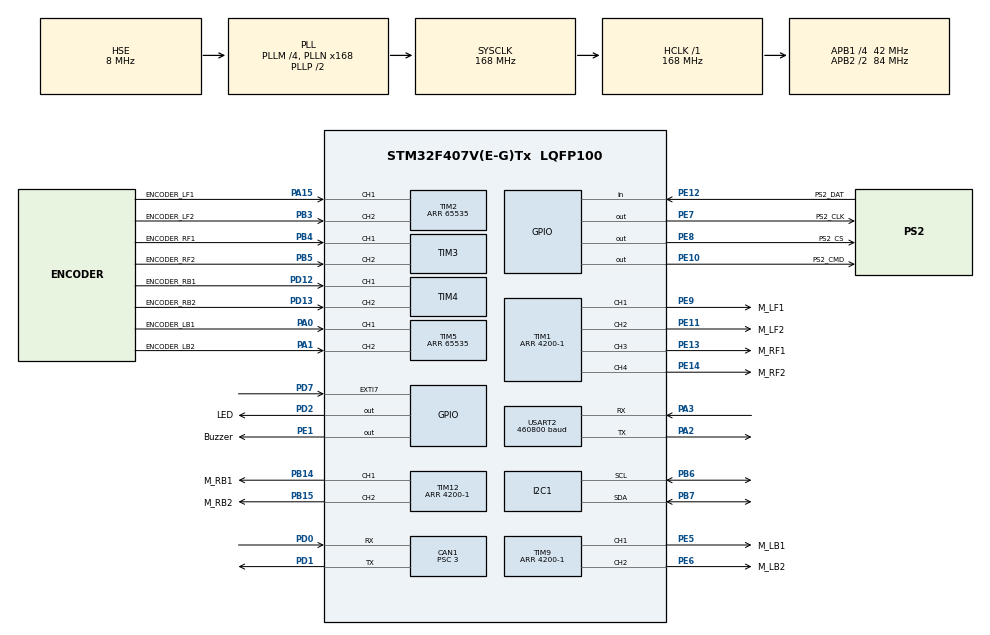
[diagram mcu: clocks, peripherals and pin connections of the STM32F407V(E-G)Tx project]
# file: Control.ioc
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CAN1.ABOM=ENABLE
CAN1.AWUM=ENABLE
CAN1.BS1=CAN_BS1_10TQ
CAN1.BS2=CAN_BS2_3TQ
CAN1.CalculateBaudRate=1000000
CAN1.CalculateTimeBit=1000
CAN1.CalculateTimeQuantum=71.42857142857143
CAN1.NART=ENABLE
CAN1.Prescaler=3
CAN1.TXFP=ENABLE
Dma.Request0=USART2_RX
Dma.Request1=USART2_TX
Dma.USART2_RX.0.Direction=DMA_PERIPH_TO_MEMORY
Dma.USART2_RX.0.FIFOMode=DMA_FIFOMODE_DISABLE
Dma.USART2_RX.0.Instance=DMA1_Stream5
Dma.USART2_RX.0.MemDataAlignment=DMA_MDATAALIGN_BYTE
Dma.USART2_RX.0.MemInc=DMA_MINC_ENABLE
Dma.USART2_RX.0.Mode=DMA_CIRCULAR
Dma.USART2_RX.0.PeriphDataAlignment=DMA_PDATAALIGN_BYTE
Dma.USART2_RX.0.PeriphInc=DMA_PINC_DISABLE
Dma.USART2_RX.0.Priority=DMA_PRIORITY_LOW
Dma.USART2_TX.1.Direction=DMA_MEMORY_TO_PERIPH
Dma.USART2_TX.1.FIFOMode=DMA_FIFOMODE_DISABLE
Dma.USART2_TX.1.Instance=DMA1_Stream6
Dma.USART2_TX.1.MemDataAlignment=DMA_MDATAALIGN_BYTE
Dma.USART2_TX.1.MemInc=DMA_MINC_ENABLE
Dma.USART2_TX.1.Mode=DMA_CIRCULAR
Dma.USART2_TX.1.PeriphDataAlignment=DMA_PDATAALIGN_BYTE
Dma.USART2_TX.1.PeriphInc=DMA_PINC_DISABLE
Dma.USART2_TX.1.Priority=DMA_PRIORITY_LOW
FREERTOS.Tasks01=MonitorTask,1,128,StartMonitorTask,As weak,NULL,Dynamic,NULL,NULL;System,-1,256,StartSystemTask,As external,NULL,Dynamic,NULL,NULL;Control,0,512,StartControlTask,As external,NULL,Dynamic,NULL,NULL
I2C1.I2C_Mode=I2C_Fast
Mcu.Family=STM32F4
Mcu.Name=STM32F407V(E-G)Tx
Mcu.Package=LQFP100
NVIC.CAN1_RX0_IRQn=true\:5\:0\:false\:false\:true\:true\:true\:true\:true
NVIC.DMA1_Stream5_IRQn=true\:5\:0\:false\:false\:true\:true\:false\:true\:true
NVIC.DMA1_Stream6_IRQn=true\:5\:0\:false\:false\:true\:true\:false\:true\:true
NVIC.EXTI9_5_IRQn=true\:5\:0\:false\:false\:true\:true\:true\:true\:true
NVIC.PriorityGroup=NVIC_PRIORITYGROUP_4
NVIC.TIM8_UP_TIM13_IRQn=true\:15\:0\:false\:false\:true\:false\:false\:true\:true
NVIC.TimeBase=TIM8_UP_TIM13_IRQn
NVIC.TimeBaseIP=TIM8
NVIC.USART2_IRQn=true\:5\:0\:false\:false\:true\:true\:false\:true\:true
PA0-WKUP.GPIO_Label=ENCODER_LB1
PA0-WKUP.GPIO_Speed=GPIO_SPEED_FREQ_VERY_HIGH
PA0-WKUP.Signal=S_TIM5_CH1
PA1.GPIO_Label=ENCODER_LB2
PA1.GPIO_Speed=GPIO_SPEED_FREQ_VERY_HIGH
PA1.Signal=S_TIM5_CH2
PA13.Mode=Serial_Wire
PA13.Signal=SYS_JTMS-SWDIO
PA14.Mode=Serial_Wire
PA14.Signal=SYS_JTCK-SWCLK
PA15.GPIO_Label=ENCODER_LF1
PA15.GPIO_PuPd=GPIO_PULLUP
PA15.GPIO_Speed=GPIO_SPEED_FREQ_VERY_HIGH
PA15.Signal=S_TIM2_CH1_ETR
PA2.Mode=Asynchronous
PA2.Signal=USART2_TX
PA3.Mode=Asynchronous
PA3.Signal=USART2_RX
PB14.GPIO_Label=M_RB1
PB14.GPIO_PuPd=GPIO_PULLUP
PB14.GPIO_Speed=GPIO_SPEED_FREQ_HIGH
PB14.Signal=S_TIM12_CH1
PB15.GPIO_Label=M_RB2
PB15.GPIO_PuPd=GPIO_PULLUP
PB15.GPIO_Speed=GPIO_SPEED_FREQ_HIGH
PB15.Signal=S_TIM12_CH2
PB3.GPIO_Label=ENCODER_LF2
PB3.GPIO_PuPd=GPIO_PULLUP
PB3.GPIO_Speed=GPIO_SPEED_FREQ_VERY_HIGH
PB3.Signal=S_TIM2_CH2
PB4.GPIO_Label=ENCODER_RF1
PB4.GPIO_Speed=GPIO_SPEED_FREQ_VERY_HIGH
PB4.Signal=S_TIM3_CH1
PB5.GPIO_Label=ENCODER_RF2
PB5.GPIO_Speed=GPIO_SPEED_FREQ_VERY_HIGH
PB5.Signal=S_TIM3_CH2
PB6.GPIO_Pu=GPIO_PULLUP
PB6.Mode=I2C
PB6.Signal=I2C1_SCL
PB7.GPIO_Pu=GPIO_PULLUP
PB7.Mode=I2C
PB7.Signal=I2C1_SDA
PD0.Mode=CAN_Activate
PD0.Signal=CAN1_RX
PD1.Mode=CAN_Activate
PD1.Signal=CAN1_TX
PD12.GPIO_Label=ENCODER_RB1
PD12.GPIO_Speed=GPIO_SPEED_FREQ_VERY_HIGH
PD12.Signal=S_TIM4_CH1
PD13.GPIO_Label=ENCODER_RB2
PD13.GPIO_Speed=GPIO_SPEED_FREQ_VERY_HIGH
PD13.Signal=S_TIM4_CH2
PD2.GPIO_Label=LED
PD2.GPIO_Speed=GPIO_SPEED_FREQ_HIGH
PD2.Signal=GPIO_Output
PD7.GPIO_ModeDefaultEXTI=GPIO_MODE_IT_RISING_FALLING
PD7.GPIO_PuPd=GPIO_PULLUP
PD7.Signal=GPXTI7
PE1.GPIO_Label=Buzzer
PE1.GPIO_Speed=GPIO_SPEED_FREQ_HIGH
PE1.Signal=GPIO_Output
PE10.GPIO_Label=PS2_CMD
PE10.GPIO_PuPd=GPIO_PULLUP
PE10.GPIO_Speed=GPIO_SPEED_FREQ_HIGH
PE10.PinState=GPIO_PIN_SET
PE10.Signal=GPIO_Output
PE11.GPIO_Label=M_LF2
PE11.GPIO_PuPd=GPIO_PULLUP
PE11.GPIO_Speed=GPIO_SPEED_FREQ_HIGH
PE11.Signal=S_TIM1_CH2
PE12.GPIO_Label=PS2_DAT
PE12.GPIO_PuPd=GPIO_PULLUP
PE12.Signal=GPIO_Input
PE13.GPIO_Label=M_RF1
PE13.GPIO_PuPd=GPIO_PULLUP
PE13.GPIO_Speed=GPIO_SPEED_FREQ_HIGH
PE13.Signal=S_TIM1_CH3
PE14.GPIO_Label=M_RF2
PE14.GPIO_PuPd=GPIO_PULLUP
PE14.GPIO_Speed=GPIO_SPEED_FREQ_HIGH
PE14.Signal=S_TIM1_CH4
PE5.GPIO_Label=M_LB1
PE5.GPIO_PuPd=GPIO_PULLUP
PE5.GPIO_Speed=GPIO_SPEED_FREQ_HIGH
PE5.Signal=S_TIM9_CH1
PE6.GPIO_Label=M_LB2
PE6.GPIO_PuPd=GPIO_PULLUP
PE6.GPIO_Speed=GPIO_SPEED_FREQ_HIGH
PE6.Signal=S_TIM9_CH2
PE7.GPIO_Label=PS2_CLK
PE7.GPIO_PuPd=GPIO_PULLUP
PE7.GPIO_Speed=GPIO_SPEED_FREQ_HIGH
PE7.PinState=GPIO_PIN_SET
PE7.Signal=GPIO_Output
PE8.GPIO_Label=PS2_CS
PE8.GPIO_PuPd=GPIO_PULLUP
PE8.GPIO_Speed=GPIO_SPEED_FREQ_HIGH
PE8.PinState=GPIO_PIN_SET
PE8.Signal=GPIO_Output
PE9.GPIO_Label=M_LF1
PE9.GPIO_PuPd=GPIO_PULLUP
PE9.GPIO_Speed=GPIO_SPEED_FREQ_HIGH
PE9.Signal=S_TIM1_CH1
PH0-OSC_IN.Mode=HSE-External-Oscillator
PH0-OSC_IN.Signal=RCC_OSC_IN
PH1-OSC_OUT.Mode=HSE-External-Oscillator
PH1-OSC_OUT.Signal=RCC_OSC_OUT
ProjectManager.HeapSize=0x200
ProjectManager.StackSize=0x400
ProjectManager.TargetToolchain=MDK-ARM V5.32
RCC.48MHZClocksFreq_Value=84000000
RCC.AHBFreq_Value=168000000
RCC.APB1CLKDivider=RCC_HCLK_DIV4
RCC.APB1Freq_Value=42000000
RCC.APB1TimFreq_Value=84000000
RCC.APB2CLKDivider=RCC_HCLK_DIV2
RCC.APB2Freq_Value=84000000
RCC.APB2TimFreq_Value=168000000
RCC.CortexFreq_Value=168000000
RCC.HCLKFreq_Value=168000000
RCC.HSE_VALUE=8000000
RCC.HSI_VALUE=16000000
RCC.LSE_VALUE=32768
RCC.PLLM=4
RCC.PLLN=168
RCC.PLLSourceVirtual=RCC_PLLSOURCE_HSE
RCC.SYSCLKFreq_VALUE=168000000
RCC.SYSCLKSource=RCC_SYSCLKSOURCE_PLLCLK
RCC.VCOOutputFreq_Value=336000000
SH.S_TIM12_CH1.0=TIM12_CH1,PWM Generation1 CH1
SH.S_TIM12_CH2.0=TIM12_CH2,PWM Generation2 CH2
SH.S_TIM1_CH1.0=TIM1_CH1,PWM Generation1 CH1
SH.S_TIM1_CH2.0=TIM1_CH2,PWM Generation2 CH2
SH.S_TIM1_CH3.0=TIM1_CH3,PWM Generation3 CH3
SH.S_TIM1_CH4.0=TIM1_CH4,PWM Generation4 CH4
SH.S_TIM2_CH1_ETR.0=TIM2_CH1,Encoder_Interface
SH.S_TIM2_CH2.0=TIM2_CH2,Encoder_Interface
SH.S_TIM3_CH1.0=TIM3_CH1,Encoder_Interface
SH.S_TIM3_CH2.0=TIM3_CH2,Encoder_Interface
SH.S_TIM4_CH1.0=TIM4_CH1,Encoder_Interface
SH.S_TIM4_CH2.0=TIM4_CH2,Encoder_Interface
SH.S_TIM5_CH1.0=TIM5_CH1,Encoder_Interface
SH.S_TIM5_CH2.0=TIM5_CH2,Encoder_Interface
SH.S_TIM9_CH1.0=TIM9_CH1,PWM Generation1 CH1
SH.S_TIM9_CH2.0=TIM9_CH2,PWM Generation2 CH2
TIM1.AutoReloadPreload=TIM_AUTORELOAD_PRELOAD_ENABLE
TIM1.AutomaticOutput=TIM_AUTOMATICOUTPUT_ENABLE
TIM1.BreakState=TIM_BREAK_ENABLE
TIM1.Channel-PWM\ Generation1\ CH1=TIM_CHANNEL_1
TIM1.Channel-PWM\ Generation2\ CH2=TIM_CHANNEL_2
TIM1.Channel-PWM\ Generation3\ CH3=TIM_CHANNEL_3
TIM1.Channel-PWM\ Generation4\ CH4=TIM_CHANNEL_4
TIM1.LockLevel=TIM_LOCKLEVEL_1
TIM1.Period=4200-1
TIM10.AutoReloadPreload=TIM_AUTORELOAD_PRELOAD_ENABLE
TIM10.Period=20000-1
TIM10.Prescaler=168-1
TIM11.AutoReloadPreload=TIM_AUTORELOAD_PRELOAD_ENABLE
TIM11.Period=20000-1
TIM11.Prescaler=168-1
TIM12.AutoReloadPreload=TIM_AUTORELOAD_PRELOAD_ENABLE
TIM12.Channel-PWM\ Generation1\ CH1=TIM_CHANNEL_1
TIM12.Channel-PWM\ Generation2\ CH2=TIM_CHANNEL_2
TIM12.Period=4200-1
TIM2.EncoderMode=TIM_ENCODERMODE_TI12
TIM2.Period=65535
TIM3.EncoderMode=TIM_ENCODERMODE_TI12
TIM4.EncoderMode=TIM_ENCODERMODE_TI12
TIM5.EncoderMode=TIM_ENCODERMODE_TI12
TIM5.Period=65535
TIM9.AutoReloadPreload=TIM_AUTORELOAD_PRELOAD_ENABLE
TIM9.Channel-PWM\ Generation1\ CH1=TIM_CHANNEL_1
TIM9.Channel-PWM\ Generation2\ CH2=TIM_CHANNEL_2
TIM9.Period=4200-1
USART2.BaudRate=460800
USART2.VirtualMode=VM_ASYNC
VP_FREERTOS_VS_CMSIS_V1.Mode=CMSIS_V1
VP_IWDG_VS_IWDG.Mode=IWDG_Activate
VP_SYS_VS_tim8.Mode=TIM8
VP_TIM10_VS_ClockSourceINT.Mode=Enable_Timer
VP_TIM11_VS_ClockSourceINT.Mode=Enable_Timer
board=custom

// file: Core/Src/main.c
/* USER CODE BEGIN Header */
/**
  ******************************************************************************
  * @file           : main.c
  * @brief          : Main program body
  ******************************************************************************
  * @attention
  *
  * Copyright (c) 2025 STMicroelectronics.
  * All rights reserved.
  *
  * This software is licensed under terms that can be found in the LICENSE file
  * in the root directory of this software component.
  * If no LICENSE file comes with this software, it is provided AS-IS.
  *
  ******************************************************************************
  */
/* USER CODE END Header */
#include "main.h"
#include "cmsis_os.h"
#include "can.h"
#include "dma.h"
#include "i2c.h"
#include "iwdg.h"
#include "tim.h"
#include "usart.h"
#include "gpio.h"

/* USER CODE BEGIN Includes */
#include "device.h"
#include "can_drv.h"
#include "uart_drv.h"
/* USER CODE END Includes */

void SystemClock_Config(void);
void MX_FREERTOS_Init(void);

/* USER CODE BEGIN 0 */
#
/* USER CODE END 0 */

int main(void)
{

  /* MCU Configuration--------------------------------------------------------*/

  /* Reset of all peripherals, Initializes the Flash interface and the Systick. */
  HAL_Init();

  /* Configure the system clock */
  SystemClock_Config();

  /* Initialize all configured peripherals */
  MX_GPIO_Init();
  MX_DMA_Init();
  MX_USART2_UART_Init();
  MX_TIM1_Init();
  MX_TIM2_Init();
  MX_TIM3_Init();
  MX_TIM4_Init();
  MX_TIM5_Init();
  MX_TIM9_Init();
  MX_TIM12_Init();
  MX_TIM10_Init();
  MX_TIM11_Init();
  MX_CAN1_Init();
  MX_I2C1_Init();
  MX_IWDG_Init();
  /* USER CODE BEGIN 2 */
	Device_Init();
	CAN1_Init();
	USART2_Init();
  /* USER CODE END 2 */

  /* Call init function for freertos objects (in cmsis_os2.c) */
  MX_FREERTOS_Init();

  /* Start scheduler */
  osKernelStart();

  /* We should never get here as control is now taken by the scheduler */

  /* Infinite loop */
  while (1)
  {

  }
}

void SystemClock_Config(void)
{
  RCC_OscInitTypeDef RCC_OscInitStruct = {0};
  RCC_ClkInitTypeDef RCC_ClkInitStruct = {0};

  /** Configure the main internal regulator output voltage
  */
  __HAL_RCC_PWR_CLK_ENABLE();
  __HAL_PWR_VOLTAGESCALING_CONFIG(PWR_REGULATOR_VOLTAGE_SCALE1);

  /** Initializes the RCC Oscillators according to the specified parameters
  * in the RCC_OscInitTypeDef structure.
  */
  RCC_OscInitStruct.OscillatorType = RCC_OSCILLATORTYPE_LSI|RCC_OSCILLATORTYPE_HSE;
  RCC_OscInitStruct.HSEState = RCC_HSE_ON;
  RCC_OscInitStruct.LSIState = RCC_LSI_ON;
  RCC_OscInitStruct.PLL.PLLState = RCC_PLL_ON;
  RCC_OscInitStruct.PLL.PLLSource = RCC_PLLSOURCE_HSE;
  RCC_OscInitStruct.PLL.PLLM = 4;
  RCC_OscInitStruct.PLL.PLLN = 168;
  RCC_OscInitStruct.PLL.PLLP = RCC_PLLP_DIV2;
  RCC_OscInitStruct.PLL.PLLQ = 4;
  if (HAL_RCC_OscConfig(&RCC_OscInitStruct) != HAL_OK)
  {
    Error_Handler();
  }

  /** Initializes the CPU, AHB and APB buses clocks
  */
  RCC_ClkInitStruct.ClockType = RCC_CLOCKTYPE_HCLK|RCC_CLOCKTYPE_SYSCLK
                              |RCC_CLOCKTYPE_PCLK1|RCC_CLOCKTYPE_PCLK2;
  RCC_ClkInitStruct.SYSCLKSource = RCC_SYSCLKSOURCE_PLLCLK;
  RCC_ClkInitStruct.AHBCLKDivider = RCC_SYSCLK_DIV1;
  RCC_ClkInitStruct.APB1CLKDivider = RCC_HCLK_DIV4;
  RCC_ClkInitStruct.APB2CLKDivider = RCC_HCLK_DIV2;

  if (HAL_RCC_ClockConfig(&RCC_ClkInitStruct, FLASH_LATENCY_5) != HAL_OK)
  {
    Error_Handler();
  }
}

void HAL_TIM_PeriodElapsedCallback(TIM_HandleTypeDef *htim)
{
  if (htim->Instance == TIM8)
  {
    HAL_IncTick();
  }
}

void Error_Handler(void)
{
  __disable_irq();
  while (1)
  {
  }
}

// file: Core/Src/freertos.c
/* USER CODE BEGIN Header */
/**
  ******************************************************************************
  * File Name          : freertos.c
  * Description        : Code for freertos applications
  ******************************************************************************
  * @attention
  *
  * Copyright (c) 2025 STMicroelectronics.
  * All rights reserved.
  *
  * This software is licensed under terms that can be found in the LICENSE file
  * in the root directory of this software component.
  * If no LICENSE file comes with this software, it is provided AS-IS.
  *
  ******************************************************************************
  */
/* USER CODE END Header */

#include "FreeRTOS.h"
#include "task.h"
#include "main.h"
#include "cmsis_os.h"

osThreadId MonitorTaskHandle;
osThreadId SystemHandle;
osThreadId ControlHandle;

void StartMonitorTask(void const * argument);
extern void StartSystemTask(void const * argument);
extern void StartControlTask(void const * argument);

void MX_FREERTOS_Init(void); /* (MISRA C 2004 rule 8.1) */

/* GetIdleTaskMemory prototype (linked to static allocation support) */
void vApplicationGetIdleTaskMemory( StaticTask_t **ppxIdleTaskTCBBuffer, StackType_t **ppxIdleTaskStackBuffer, uint32_t *pulIdleTaskStackSize );

/* USER CODE BEGIN GET_IDLE_TASK_MEMORY */
static StaticTask_t xIdleTaskTCBBuffer;
static StackType_t xIdleStack[configMINIMAL_STACK_SIZE];

void vApplicationGetIdleTaskMemory( StaticTask_t **ppxIdleTaskTCBBuffer, StackType_t **ppxIdleTaskStackBuffer, uint32_t *pulIdleTaskStackSize )
{
  *ppxIdleTaskTCBBuffer = &xIdleTaskTCBBuffer;
  *ppxIdleTaskStackBuffer = &xIdleStack[0];
  *pulIdleTaskStackSize = configMINIMAL_STACK_SIZE;
  /* place for user code */
}
/* USER CODE END GET_IDLE_TASK_MEMORY */

void MX_FREERTOS_Init(void) {

  /* Create the thread(s) */
  /* definition and creation of MonitorTask */
  osThreadDef(MonitorTask, StartMonitorTask, osPriorityAboveNormal, 0, 128);
  MonitorTaskHandle = osThreadCreate(osThread(MonitorTask), NULL);

  /* definition and creation of System */
  osThreadDef(System, StartSystemTask, osPriorityBelowNormal, 0, 256);
  SystemHandle = osThreadCreate(osThread(System), NULL);

  /* definition and creation of Control */
  osThreadDef(Control, StartControlTask, osPriorityNormal, 0, 512);
  ControlHandle = osThreadCreate(osThread(Control), NULL);

}

__weak void StartMonitorTask(void const * argument)
{
  for(;;)
  {
    osDelay(1);
  }
}
